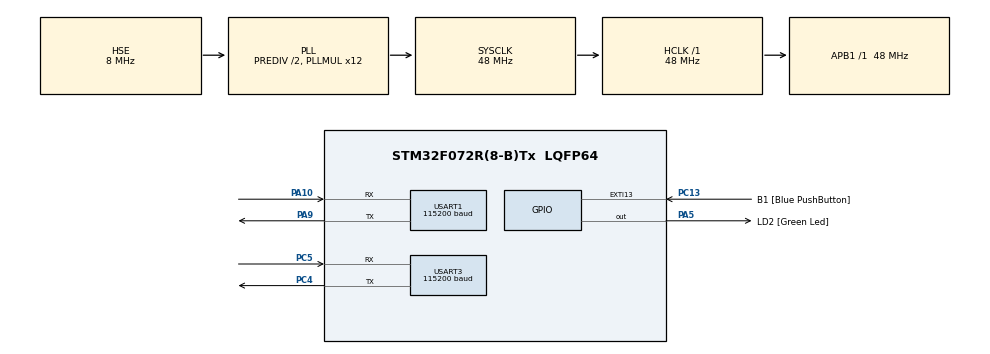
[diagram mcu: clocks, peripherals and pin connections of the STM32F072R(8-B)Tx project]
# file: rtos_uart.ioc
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FREERTOS.BinarySemaphores01=BinarySem_parser,Dynamic,NULL,Depleted
FREERTOS.Queues01=debugQueue,16,uint16_t,0,Dynamic,NULL,NULL
FREERTOS.Tasks01=Task1,24,128,StartTask1,Default,NULL,Dynamic,NULL,NULL;Task2,8,128,StartTask2,Default,NULL,Dynamic,NULL,NULL
FREERTOS.configUSE_NEWLIB_REENTRANT=1
Mcu.Family=STM32F0
Mcu.Name=STM32F072R(8-B)Tx
Mcu.Package=LQFP64
NVIC.TIM17_IRQn=true\:3\:0\:false\:false\:true\:false\:false\:true\:true
NVIC.TIM1_BRK_UP_TRG_COM_IRQn=true\:3\:0\:false\:false\:true\:true\:true\:true\:true
NVIC.TIM2_IRQn=true\:3\:0\:false\:false\:true\:true\:true\:true\:true
NVIC.TimeBase=TIM17_IRQn
NVIC.TimeBaseIP=TIM17
NVIC.USART1_IRQn=true\:3\:0\:false\:false\:true\:true\:true\:true\:true
NVIC.USART3_4_IRQn=true\:3\:0\:false\:false\:true\:true\:true\:true\:true
PA10.Mode=Asynchronous
PA10.Signal=USART1_RX
PA13.GPIO_Label=TMS
PA13.Mode=Serial_Wire
PA13.Signal=SYS_SWDIO
PA14.GPIO_Label=TCK
PA14.Mode=Serial_Wire
PA14.Signal=SYS_SWCLK
PA5.GPIO_Label=LD2 [Green Led]
PA5.GPIO_Mode=GPIO_MODE_OUTPUT_PP
PA5.GPIO_PuPd=GPIO_NOPULL
PA5.GPIO_Speed=GPIO_SPEED_FREQ_LOW
PA5.Signal=GPIO_Output
PA9.Mode=Asynchronous
PA9.Signal=USART1_TX
PC13.GPIO_Label=B1 [Blue PushButton]
PC13.GPIO_ModeDefaultEXTI=GPIO_MODE_IT_FALLING
PC13.Signal=GPXTI13
PC14-OSC32_IN.Mode=LSE-External-Oscillator
PC14-OSC32_IN.Signal=RCC_OSC32_IN
PC15-OSC32_OUT.Mode=LSE-External-Oscillator
PC15-OSC32_OUT.Signal=RCC_OSC32_OUT
PC4.Mode=Asynchronous
PC4.Signal=USART3_TX
PC5.Mode=Asynchronous
PC5.Signal=USART3_RX
PF0-OSC_IN.Mode=HSE-External-Clock-Source
PF0-OSC_IN.Signal=RCC_OSC_IN
PF1-OSC_OUT.Signal=RCC_OSC_OUT
ProjectManager.HeapSize=0x200
ProjectManager.StackSize=0x400
ProjectManager.TargetToolchain=STM32CubeIDE
RCC.AHBFreq_Value=48000000
RCC.APB1Freq_Value=48000000
RCC.APB1TimFreq_Value=48000000
RCC.FLatency-AdvancedSettings=FLASH_LATENCY_1
RCC.HCLKFreq_Value=48000000
RCC.PLLDivider=RCC_PREDIV_DIV2
RCC.PLLMUL=RCC_PLL_MUL12
RCC.PLLSourceVirtual=RCC_PLLSOURCE_HSE
RCC.PREFETCH_ENABLE-AdvancedSettings=1
RCC.SYSCLKFreq_VALUE=48000000
RCC.SYSCLKSource=RCC_SYSCLKSOURCE_PLLCLK
TIM1.Period=4799
TIM2.Period=47999
USART1.BaudRate=115200
USART1.VirtualMode-Asynchronous=VM_ASYNC
USART3.BaudRate=115200
USART3.VirtualMode-Asynchronous=VM_ASYNC
VP_FREERTOS_VS_CMSIS_V2.Mode=CMSIS_V2
VP_SYS_VS_tim17.Mode=TIM17
VP_TIM1_VS_ClockSourceINT.Mode=Internal
VP_TIM2_VS_ClockSourceINT.Mode=Internal
board=NUCLEO-F072RB

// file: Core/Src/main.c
/* USER CODE BEGIN Header */
/**
  ******************************************************************************
  * @file           : main.c
  * @brief          : Main program body
  ******************************************************************************
  * @attention
  *
  * Copyright (c) 2026 STMicroelectronics.
  * All rights reserved.
  *
  * This software is licensed under terms that can be found in the LICENSE file
  * in the root directory of this software component.
  * If no LICENSE file comes with this software, it is provided AS-IS.
  *
  ******************************************************************************
  */
/* USER CODE END Header */
#include "main.h"
#include "cmsis_os.h"
#include "tim.h"
#include "usart.h"
#include "gpio.h"

void SystemClock_Config(void);
void MX_FREERTOS_Init(void);

int main(void)
{

  /* MCU Configuration--------------------------------------------------------*/

  /* Reset of all peripherals, Initializes the Flash interface and the Systick. */
  HAL_Init();

  /* Configure the system clock */
  SystemClock_Config();

  /* Initialize all configured peripherals */
  MX_GPIO_Init();
  MX_TIM1_Init();
  MX_TIM2_Init();
  MX_USART1_UART_Init();
  MX_USART3_UART_Init();
  /* USER CODE BEGIN 2 */

  HAL_UART_Transmit(&huart1, (uint8_t*)"start", strlen("start"), 100);
  HAL_UART_Receive_IT(&huart3, &rx_byte, 1);
  /* USER CODE END 2 */

  /* Init scheduler */
  osKernelInitialize();  /* Call init function for freertos objects (in cmsis_os2.c) */
  MX_FREERTOS_Init();

  /* Start scheduler */
  osKernelStart();

  /* We should never get here as control is now taken by the scheduler */

  /* Infinite loop */
  while (1)
  {

  }
}

void SystemClock_Config(void)
{
  RCC_OscInitTypeDef RCC_OscInitStruct = {0};
  RCC_ClkInitTypeDef RCC_ClkInitStruct = {0};
  RCC_PeriphCLKInitTypeDef PeriphClkInit = {0};

  /** Initializes the RCC Oscillators according to the specified parameters
  * in the RCC_OscInitTypeDef structure.
  */
  RCC_OscInitStruct.OscillatorType = RCC_OSCILLATORTYPE_HSE;
  RCC_OscInitStruct.HSEState = RCC_HSE_BYPASS;
  RCC_OscInitStruct.PLL.PLLState = RCC_PLL_ON;
  RCC_OscInitStruct.PLL.PLLSource = RCC_PLLSOURCE_HSE;
  RCC_OscInitStruct.PLL.PLLMUL = RCC_PLL_MUL12;
  RCC_OscInitStruct.PLL.PREDIV = RCC_PREDIV_DIV2;
  if (HAL_RCC_OscConfig(&RCC_OscInitStruct) != HAL_OK)
  {
    Error_Handler();
  }

  /** Initializes the CPU, AHB and APB buses clocks
  */
  RCC_ClkInitStruct.ClockType = RCC_CLOCKTYPE_HCLK|RCC_CLOCKTYPE_SYSCLK
                              |RCC_CLOCKTYPE_PCLK1;
  RCC_ClkInitStruct.SYSCLKSource = RCC_SYSCLKSOURCE_PLLCLK;
  RCC_ClkInitStruct.AHBCLKDivider = RCC_SYSCLK_DIV1;
  RCC_ClkInitStruct.APB1CLKDivider = RCC_HCLK_DIV1;

  if (HAL_RCC_ClockConfig(&RCC_ClkInitStruct, FLASH_LATENCY_1) != HAL_OK)
  {
    Error_Handler();
  }
  PeriphClkInit.PeriphClockSelection = RCC_PERIPHCLK_USART1;
  PeriphClkInit.Usart1ClockSelection = RCC_USART1CLKSOURCE_PCLK1;
  if (HAL_RCCEx_PeriphCLKConfig(&PeriphClkInit) != HAL_OK)
  {
    Error_Handler();
  }
}

void HAL_TIM_PeriodElapsedCallback(TIM_HandleTypeDef *htim)
{
  if (htim->Instance == TIM17)
  {
    HAL_IncTick();
  }
}

void Error_Handler(void)
{
  __disable_irq();
  while (1)
  {
  }
}

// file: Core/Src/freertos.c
/* USER CODE BEGIN Header */
/**
  ******************************************************************************
  * File Name          : freertos.c
  * Description        : Code for freertos applications
  ******************************************************************************
  * @attention
  *
  * Copyright (c) 2026 STMicroelectronics.
  * All rights reserved.
  *
  * This software is licensed under terms that can be found in the LICENSE file
  * in the root directory of this software component.
  * If no LICENSE file comes with this software, it is provided AS-IS.
  *
  ******************************************************************************
  */
/* USER CODE END Header */

#include "FreeRTOS.h"
#include "task.h"
#include "main.h"
#include "cmsis_os.h"

/* USER CODE BEGIN Includes */
#include <usart.h>
#include <string.h>
/* USER CODE END Includes */

/* Definitions for Task1 */
osThreadId_t Task1Handle;
const osThreadAttr_t Task1_attributes = {
  .name = "Task1",
  .stack_size = 128 * 4,
  .priority = (osPriority_t) osPriorityNormal,
};
/* Definitions for Task2 */
osThreadId_t Task2Handle;
const osThreadAttr_t Task2_attributes = {
  .name = "Task2",
  .stack_size = 128 * 4,
  .priority = (osPriority_t) osPriorityLow,
};
/* Definitions for debugQueue */
osMessageQueueId_t debugQueueHandle;
const osMessageQueueAttr_t debugQueue_attributes = {
  .name = "debugQueue"
};
/* Definitions for BinarySem_parser */
osSemaphoreId_t BinarySem_parserHandle;
const osSemaphoreAttr_t BinarySem_parser_attributes = {
  .name = "BinarySem_parser"
};

void StartTask1(void *argument);
void StartTask2(void *argument);

void MX_FREERTOS_Init(void); /* (MISRA C 2004 rule 8.1) */

void MX_FREERTOS_Init(void) {

  /* Create the semaphores(s) */
  /* creation of BinarySem_parser */
  BinarySem_parserHandle = osSemaphoreNew(1, 0, &BinarySem_parser_attributes);

  /* Create the queue(s) */
  /* creation of debugQueue */
  debugQueueHandle = osMessageQueueNew (16, sizeof(uint16_t), &debugQueue_attributes);

  /* Create the thread(s) */
  /* creation of Task1 */
  Task1Handle = osThreadNew(StartTask1, NULL, &Task1_attributes);

  /* creation of Task2 */
  Task2Handle = osThreadNew(StartTask2, NULL, &Task2_attributes);

}

void StartTask1(void *argument)
{
  /* USER CODE BEGIN StartTask1 */
  /* Infinite loop */
  for(;;)
  {
	  osSemaphoreAcquire(BinarySem_parserHandle, osWaitForever);
	  process_command();
  }
  /* USER CODE END StartTask1 */
}

void StartTask2(void *argument)
{
  /* USER CODE BEGIN StartTask2 */
  /* Infinite loop */
  for(;;)
  {
	  if (xQueueReceive(debugQueueHandle, &rx_byte, portMAX_DELAY))
	      {
	          HAL_UART_Transmit(&huart1, &rx_byte, 1, 100);
	      }
  }
  /* USER CODE END StartTask2 */
}
